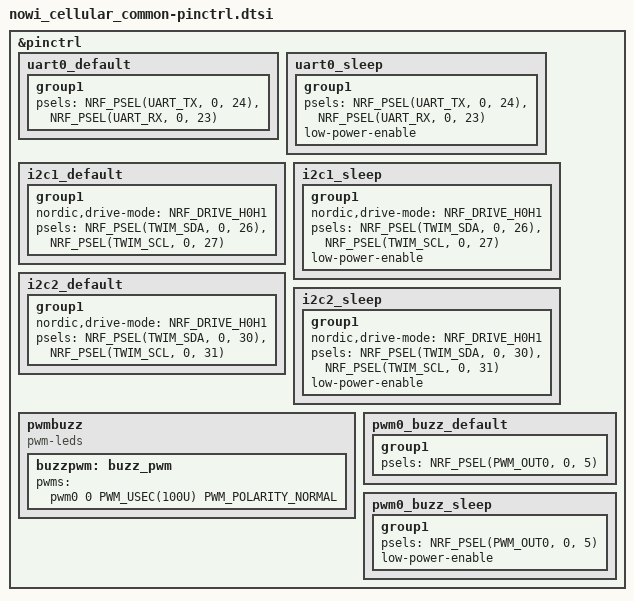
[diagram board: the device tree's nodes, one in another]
/*
 * Copyright (c) 2022 Nordic Semiconductor
 * SPDX-License-Identifier: Apache-2.0
 */

 &pinctrl {
	uart0_default: uart0_default {
		group1 {
			psels = <NRF_PSEL(UART_TX, 0, 24)>,
					<NRF_PSEL(UART_RX, 0, 23)>;
		};
	};

	uart0_sleep: uart0_sleep {
		group1 {
			psels = <NRF_PSEL(UART_TX, 0, 24)>,
					<NRF_PSEL(UART_RX, 0, 23)>;
			low-power-enable;
		};
	};
	
	i2c1_default: i2c1_default {
		group1 {
			nordic,drive-mode = <NRF_DRIVE_H0H1>;
			psels = <NRF_PSEL(TWIM_SDA, 0, 26)>,
					<NRF_PSEL(TWIM_SCL, 0, 27)>;
		};
	};

	i2c1_sleep: i2c1_sleep {
		group1 {
			nordic,drive-mode = <NRF_DRIVE_H0H1>;
			psels = <NRF_PSEL(TWIM_SDA, 0, 26)>,
					<NRF_PSEL(TWIM_SCL, 0, 27)>;
			low-power-enable;
		};
	};

	i2c2_default: i2c2_default {
		group1 {
			nordic,drive-mode = <NRF_DRIVE_H0H1>;
			psels = <NRF_PSEL(TWIM_SDA, 0, 30)>,
					<NRF_PSEL(TWIM_SCL, 0, 31)>;
		};
	};

	i2c2_sleep: i2c2_sleep {
		group1 {
			nordic,drive-mode = <NRF_DRIVE_H0H1>;
			psels = <NRF_PSEL(TWIM_SDA, 0, 30)>,
					<NRF_PSEL(TWIM_SCL, 0, 31)>;
			low-power-enable;
		};
	};

	pwmbuzz {
		compatible = "pwm-leds";
		buzzpwm: buzz_pwm {
			pwms = <&pwm0 0 PWM_USEC(100U) PWM_POLARITY_NORMAL>;
		};
	};

	pwm0_buzz_default: pwm0_buzz_default {
		group1 {
			psels = <NRF_PSEL(PWM_OUT0, 0, 5)>;
			//nordic,invert;
		};
	};

	pwm0_buzz_sleep: pwm0_buzz_sleep {
		group1 {
			psels = <NRF_PSEL(PWM_OUT0, 0, 5)>;
			low-power-enable;
		};
	};
};
